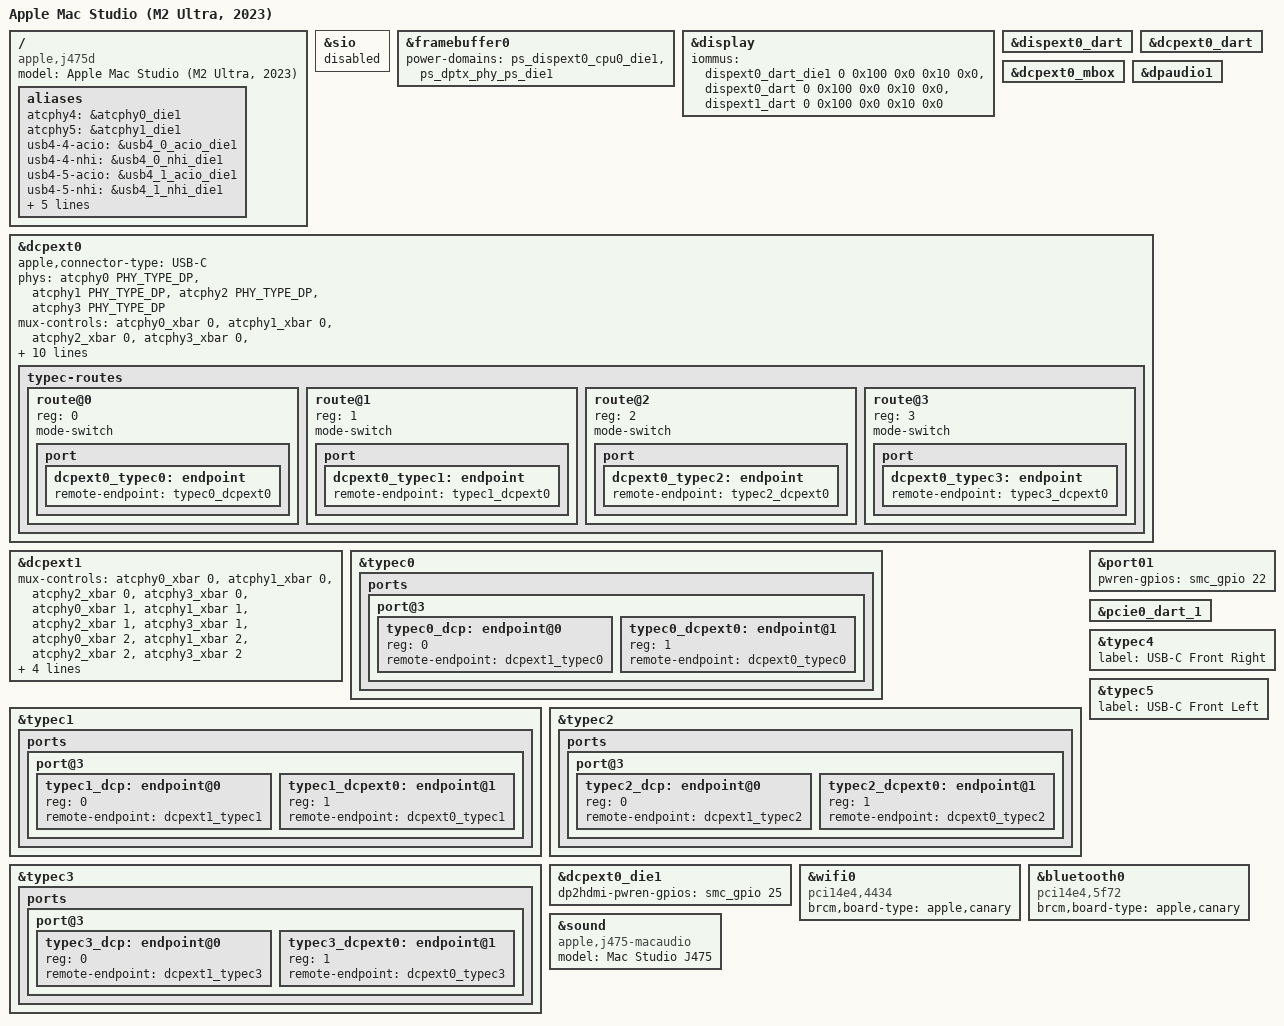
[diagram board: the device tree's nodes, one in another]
// SPDX-License-Identifier: GPL-2.0+ OR MIT
/*
 * Mac Studio (M2 Ultra, 2023)
 *
 * target-type: J475d
 *
 * Copyright The Asahi Linux Contributors
 */

/dts-v1/;

#define NO_DCP

#include "t6022.dtsi"
#include "t602x-j474-j475.dtsi"
#include "t6022-jxxxd.dtsi"

/ {
	compatible = "apple,j475d", "apple,t6022", "apple,arm-platform";
	model = "Apple Mac Studio (M2 Ultra, 2023)";

	aliases {
		atcphy4 = &atcphy0_die1;
		atcphy5 = &atcphy1_die1;
		usb4-4-acio = &usb4_0_acio_die1;
		usb4-4-nhi = &usb4_0_nhi_die1;
		usb4-5-acio = &usb4_1_acio_die1;
		usb4-5-nhi = &usb4_1_nhi_die1;

		/delete-property/ dcp;
		/delete-property/ sio;

		usb4_4_rc = &usb4_0_acio_die1;
		usb4_4_nhi = &usb4_0_nhi_die1;
		usb4_5_rc = &usb4_1_acio_die1;
		usb4_5_nhi = &usb4_1_nhi_die1;
	};
};

&sio {
	status = "disabled";
};

&framebuffer0 {
	power-domains = <&ps_dispext0_cpu0_die1>, <&ps_dptx_phy_ps_die1>;
};

/*
 * HDMI scans out through dispext0 on die 1, and the rear USB-C ports through
 * dcpext1/dispext1 on die 0 (see t602x-j474-j475.dtsi).
 */
&display {
	iommus = <&dispext0_dart_die1 0 0x100 0x0 0x10 0x0>,
		 <&dispext0_dart 0 0x100 0x0 0x10 0x0>,
		 <&dispext1_dart 0 0x100 0x0 0x10 0x0>;
};

/*
 * Thunderbolt DP tunnels on M2 need two pipelines per port with named DPIN
 * crossbar controls, as on the 14/16-inch boards. HDMI uses die 1 here, so
 * die-0 dcpext0 is free to be the second rear-port pipeline (crossbar state
 * 0, dcpext1 state 2).
 */
/ {
	aliases {
		/* m1n1 fills apple,firmware-compat through the ADT-indexed alias */
		dcpext0 = &dcpext0;
	};
};

&dispext0_dart {
	status = "okay";
};

&dcpext0_dart {
	status = "okay";
};

&dcpext0_mbox {
	status = "okay";
};

&dpaudio1 {
	status = "okay";
};

&dcpext0 {
	status = "okay";
	apple,connector-type = "USB-C";
	phys = <&atcphy0 PHY_TYPE_DP>, <&atcphy1 PHY_TYPE_DP>,
	       <&atcphy2 PHY_TYPE_DP>, <&atcphy3 PHY_TYPE_DP>;
	phy-names = "typec0", "typec1", "typec2", "typec3";
	mux-controls = <&atcphy0_xbar 0>,
		       <&atcphy1_xbar 0>,
		       <&atcphy2_xbar 0>,
		       <&atcphy3_xbar 0>,
		       <&atcphy0_xbar 1>,
		       <&atcphy1_xbar 1>,
		       <&atcphy2_xbar 1>,
		       <&atcphy3_xbar 1>,
		       <&atcphy0_xbar 2>,
		       <&atcphy1_xbar 2>,
		       <&atcphy2_xbar 2>,
		       <&atcphy3_xbar 2>;
	mux-control-names = "typec0", "typec1", "typec2", "typec3",
			    "typec0-dpin0", "typec1-dpin0", "typec2-dpin0", "typec3-dpin0",
			    "typec0-dpin1", "typec1-dpin1", "typec2-dpin1", "typec3-dpin1";
	apple,typec-mux-indices = <0 0 0 0>;
	apple,typec-dptx-phys = <0 1 2 3>;

	typec-routes {
		#address-cells = <1>;
		#size-cells = <0>;

		route@0 {
			reg = <0>;
			mode-switch;

			port {
				dcpext0_typec0: endpoint {
					remote-endpoint = <&typec0_dcpext0>;
				};
			};
		};

		route@1 {
			reg = <1>;
			mode-switch;

			port {
				dcpext0_typec1: endpoint {
					remote-endpoint = <&typec1_dcpext0>;
				};
			};
		};

		route@2 {
			reg = <2>;
			mode-switch;

			port {
				dcpext0_typec2: endpoint {
					remote-endpoint = <&typec2_dcpext0>;
				};
			};
		};

		route@3 {
			reg = <3>;
			mode-switch;

			port {
				dcpext0_typec3: endpoint {
					remote-endpoint = <&typec3_dcpext0>;
				};
			};
		};
	};
};

&dcpext1 {
	mux-controls = <&atcphy0_xbar 0>,
		       <&atcphy1_xbar 0>,
		       <&atcphy2_xbar 0>,
		       <&atcphy3_xbar 0>,
		       <&atcphy0_xbar 1>,
		       <&atcphy1_xbar 1>,
		       <&atcphy2_xbar 1>,
		       <&atcphy3_xbar 1>,
		       <&atcphy0_xbar 2>,
		       <&atcphy1_xbar 2>,
		       <&atcphy2_xbar 2>,
		       <&atcphy3_xbar 2>;
	mux-control-names = "typec0", "typec1", "typec2", "typec3",
			    "typec0-dpin0", "typec1-dpin0", "typec2-dpin0", "typec3-dpin0",
			    "typec0-dpin1", "typec1-dpin1", "typec2-dpin1", "typec3-dpin1";
};

&typec0 {
	ports {
		port@3 {
			#address-cells = <1>;
			#size-cells = <0>;
			/delete-node/ endpoint;

			typec0_dcp: endpoint@0 {
				reg = <0>;
				remote-endpoint = <&dcpext1_typec0>;
			};

			typec0_dcpext0: endpoint@1 {
				reg = <1>;
				remote-endpoint = <&dcpext0_typec0>;
			};
		};
	};
};

&typec1 {
	ports {
		port@3 {
			#address-cells = <1>;
			#size-cells = <0>;
			/delete-node/ endpoint;

			typec1_dcp: endpoint@0 {
				reg = <0>;
				remote-endpoint = <&dcpext1_typec1>;
			};

			typec1_dcpext0: endpoint@1 {
				reg = <1>;
				remote-endpoint = <&dcpext0_typec1>;
			};
		};
	};
};

&typec2 {
	ports {
		port@3 {
			#address-cells = <1>;
			#size-cells = <0>;
			/delete-node/ endpoint;

			typec2_dcp: endpoint@0 {
				reg = <0>;
				remote-endpoint = <&dcpext1_typec2>;
			};

			typec2_dcpext0: endpoint@1 {
				reg = <1>;
				remote-endpoint = <&dcpext0_typec2>;
			};
		};
	};
};

&typec3 {
	ports {
		port@3 {
			#address-cells = <1>;
			#size-cells = <0>;
			/delete-node/ endpoint;

			typec3_dcp: endpoint@0 {
				reg = <0>;
				remote-endpoint = <&dcpext1_typec3>;
			};

			typec3_dcpext0: endpoint@1 {
				reg = <1>;
				remote-endpoint = <&dcpext0_typec3>;
			};
		};
	};
};

&dcpext0_die1 {
	// J180 misses "function-dp2hdmi_pwr_en"
	dp2hdmi-pwren-gpios = <&smc_gpio 25 GPIO_ACTIVE_HIGH>;
};

/* enable PCIe port01 with SDHCI */
&port01 {
	pwren-gpios = <&smc_gpio 22 GPIO_ACTIVE_HIGH>;
	status = "okay";
};

&pcie0_dart_1 {
	status = "okay";
};

&typec4 {
	label = "USB-C Front Right";
};

&typec5 {
	label = "USB-C Front Left";
};

#include "hwmon-fan-dual.dtsi"

/* delete unused USB nodes on die 1 */
/delete-node/ &dwc3_2_dart_0_die1;
/delete-node/ &dwc3_2_dart_1_die1;
/delete-node/ &dwc3_2_die1;
/delete-node/ &atcphy2_die1;
/delete-node/ &atcphy2_xbar_die1;

/delete-node/ &dwc3_3_dart_0_die1;
/delete-node/ &dwc3_3_dart_1_die1;
/delete-node/ &dwc3_3_die1;
/delete-node/ &atcphy3_die1;
/delete-node/ &atcphy3_xbar_die1;

/delete-node/ &usb4_2_acio_die1;
/delete-node/ &usb4_2_mbox_die1;

/delete-node/ &usb4_3_acio_die1;
/delete-node/ &usb4_3_mbox_die1;

/* delete unused always-on power-domains on die 1 */
/delete-node/ &ps_atc2_usb_aon_die1;
/delete-node/ &ps_atc2_usb_die1;

/delete-node/ &ps_atc3_usb_aon_die1;
/delete-node/ &ps_atc3_usb_die1;

&wifi0 {
	compatible = "pci14e4,4434";
	brcm,board-type = "apple,canary";
};

&bluetooth0 {
	compatible = "pci14e4,5f72";
	brcm,board-type = "apple,canary";
};

&sound {
	compatible = "apple,j475-macaudio", "apple,j375-macaudio", "apple,macaudio";
	model = "Mac Studio J475";
};
